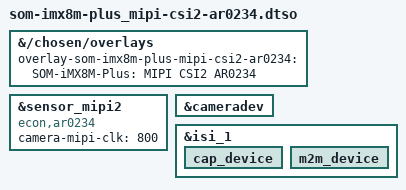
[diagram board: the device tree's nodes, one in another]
#include "overlay.h"

&{/chosen/overlays} {
	overlay-som-imx8m-plus-mipi-csi2-ar0234 = "SOM-iMX8M-Plus: MIPI CSI2 AR0234";
};

#include "som-imx8m-plus_mipi-csi2.dtsi"

&sensor_mipi2 {
	compatible = "econ,ar0234", "ar0234";
	camera-mipi-clk = <800>;
};

&cameradev {
	status = "okay";
};

&isi_1 {
	status = "okay";

	cap_device {
		status = "okay";
	};

	m2m_device {
		status = "okay";
	};
};
